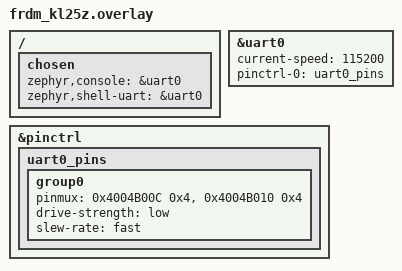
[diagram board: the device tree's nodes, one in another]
/ {
    chosen {
        zephyr,console = &uart0;
        zephyr,shell-uart = &uart0;
    };
};

/* UART0: RX = PTC3, TX = PTC4 */
&uart0 {
    status = "okay";
    current-speed = <115200>;
    pinctrl-0 = <&uart0_pins>;
    pinctrl-names = "default";
};

&pinctrl {
    uart0_pins: uart0_pins {
        group0 {
            /* PTC3 = RX, ALT4 = UART0_RX */
            /* PTC4 = TX, ALT4 = UART0_TX */
            pinmux = <0x4004B00C 0x4>, /* PTC3 ALT4 */
                     <0x4004B010 0x4>; /* PTC4 ALT4 */
            drive-strength = "low";
            slew-rate = "fast";
        };
    };
};
